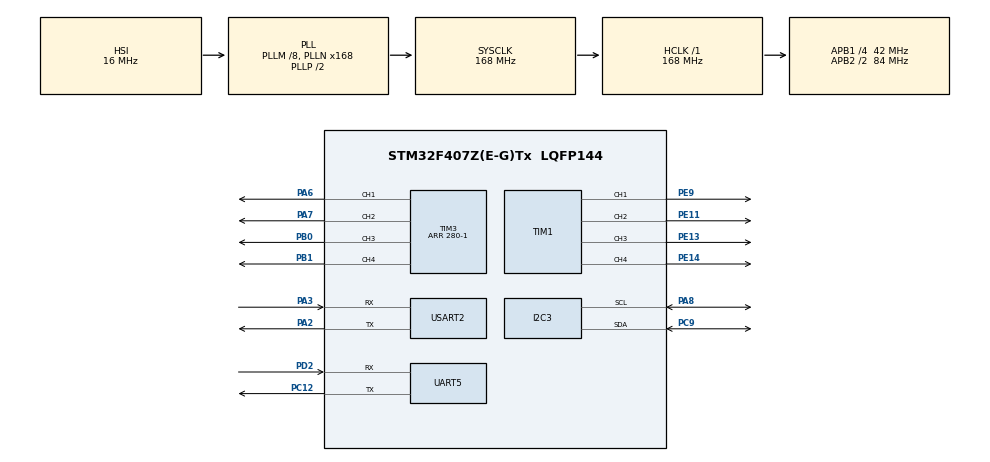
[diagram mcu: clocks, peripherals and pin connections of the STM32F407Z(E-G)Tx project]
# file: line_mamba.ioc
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Mcu.Family=STM32F4
Mcu.Name=STM32F407Z(E-G)Tx
Mcu.Package=LQFP144
NVIC.PriorityGroup=NVIC_PRIORITYGROUP_4
NVIC.USART2_IRQn=true\:5\:0\:false\:false\:true\:true\:true\:true
PA13.Mode=Serial_Wire
PA13.Signal=SYS_JTMS-SWDIO
PA14.Mode=Serial_Wire
PA14.Signal=SYS_JTCK-SWCLK
PA2.Mode=Asynchronous
PA2.Signal=USART2_TX
PA3.Mode=Asynchronous
PA3.Signal=USART2_RX
PA6.Signal=S_TIM3_CH1
PA7.Signal=S_TIM3_CH2
PA8.Mode=I2C
PA8.Signal=I2C3_SCL
PB0.Signal=S_TIM3_CH3
PB1.Signal=S_TIM3_CH4
PC12.Mode=Asynchronous
PC12.Signal=UART5_TX
PC9.Mode=I2C
PC9.Signal=I2C3_SDA
PD2.Mode=Asynchronous
PD2.Signal=UART5_RX
PE11.Signal=S_TIM1_CH2
PE13.Signal=S_TIM1_CH3
PE14.Signal=S_TIM1_CH4
PE9.Signal=S_TIM1_CH1
ProjectManager.HeapSize=0x200
ProjectManager.StackSize=0x400
ProjectManager.TargetToolchain=CMake
RCC.48MHZClocksFreq_Value=48000000
RCC.AHBFreq_Value=168000000
RCC.APB1CLKDivider=RCC_HCLK_DIV4
RCC.APB1Freq_Value=42000000
RCC.APB1TimFreq_Value=84000000
RCC.APB2CLKDivider=RCC_HCLK_DIV2
RCC.APB2Freq_Value=84000000
RCC.APB2TimFreq_Value=168000000
RCC.CortexFreq_Value=168000000
RCC.HSE_VALUE=25000000
RCC.HSI_VALUE=16000000
RCC.LSE_VALUE=32768
RCC.PLLM=8
RCC.PLLN=168
RCC.PLLQ=7
RCC.SYSCLKFreq_VALUE=168000000
RCC.SYSCLKSource=RCC_SYSCLKSOURCE_PLLCLK
RCC.VCOOutputFreq_Value=336000000
SH.S_TIM1_CH1.0=TIM1_CH1,PWM Generation1 CH1
SH.S_TIM1_CH2.0=TIM1_CH2,PWM Generation2 CH2
SH.S_TIM1_CH3.0=TIM1_CH3,PWM Generation3 CH3
SH.S_TIM1_CH4.0=TIM1_CH4,PWM Generation4 CH4
SH.S_TIM3_CH1.0=TIM3_CH1,PWM Generation1 CH1
SH.S_TIM3_CH2.0=TIM3_CH2,PWM Generation2 CH2
SH.S_TIM3_CH3.0=TIM3_CH3,PWM Generation3 CH3
SH.S_TIM3_CH4.0=TIM3_CH4,PWM Generation4 CH4
TIM1.Channel-PWM\ Generation1\ CH1=TIM_CHANNEL_1
TIM1.Channel-PWM\ Generation2\ CH2=TIM_CHANNEL_2
TIM1.Channel-PWM\ Generation3\ CH3=TIM_CHANNEL_3
TIM1.Channel-PWM\ Generation4\ CH4=TIM_CHANNEL_4
TIM3.Channel-PWM\ Generation1\ CH1=TIM_CHANNEL_1
TIM3.Channel-PWM\ Generation2\ CH2=TIM_CHANNEL_2
TIM3.Channel-PWM\ Generation3\ CH3=TIM_CHANNEL_3
TIM3.Channel-PWM\ Generation4\ CH4=TIM_CHANNEL_4
TIM3.Period=280-1
UART5.VirtualMode=Asynchronous
USART2.VirtualMode=VM_ASYNC
board=custom

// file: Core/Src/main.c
/* USER CODE BEGIN Header */
/**
  ******************************************************************************
  * @file           : main.c
  * @brief          : Main program body
  ******************************************************************************
  * @attention
  *
  * Copyright (c) 2026 STMicroelectronics.
  * All rights reserved.
  *
  * This software is licensed under terms that can be found in the LICENSE file
  * in the root directory of this software component.
  * If no LICENSE file comes with this software, it is provided AS-IS.
  *
  ******************************************************************************
  */
/* USER CODE END Header */
#include "main.h"
#include "i2c.h"
#include "tim.h"
#include "usart.h"
#include "gpio.h"

/* USER CODE BEGIN Includes */
#include "mamba_app.h"

/* USER CODE END Includes */

void SystemClock_Config(void);

int main(void)
{

  /* MCU Configuration--------------------------------------------------------*/

  /* Reset of all peripherals, Initializes the Flash interface and the Systick. */
  HAL_Init();

  /* Configure the system clock */
  SystemClock_Config();

  /* Initialize all configured peripherals */
  MX_GPIO_Init();
  MX_TIM1_Init();
  MX_TIM3_Init();
  MX_I2C3_Init();
  MX_UART5_Init();
  MX_USART2_UART_Init();
  /* USER CODE BEGIN 2 */
  MambaApp_Init();

  /* USER CODE END 2 */

  /* Infinite loop */
  while (1)
  {

    /* USER CODE BEGIN 3 */
    MambaApp_Poll();
  }
  /* USER CODE END 3 */
}

void SystemClock_Config(void)
{
  RCC_OscInitTypeDef RCC_OscInitStruct = {0};
  RCC_ClkInitTypeDef RCC_ClkInitStruct = {0};

  /** Configure the main internal regulator output voltage
  */
  __HAL_RCC_PWR_CLK_ENABLE();
  __HAL_PWR_VOLTAGESCALING_CONFIG(PWR_REGULATOR_VOLTAGE_SCALE1);

  /** Initializes the RCC Oscillators according to the specified parameters
  * in the RCC_OscInitTypeDef structure.
  */
  RCC_OscInitStruct.OscillatorType = RCC_OSCILLATORTYPE_HSI;
  RCC_OscInitStruct.HSIState = RCC_HSI_ON;
  RCC_OscInitStruct.HSICalibrationValue = RCC_HSICALIBRATION_DEFAULT;
  RCC_OscInitStruct.PLL.PLLState = RCC_PLL_ON;
  RCC_OscInitStruct.PLL.PLLSource = RCC_PLLSOURCE_HSI;
  RCC_OscInitStruct.PLL.PLLM = 8;
  RCC_OscInitStruct.PLL.PLLN = 168;
  RCC_OscInitStruct.PLL.PLLP = RCC_PLLP_DIV2;
  RCC_OscInitStruct.PLL.PLLQ = 7;
  if (HAL_RCC_OscConfig(&RCC_OscInitStruct) != HAL_OK)
  {
    Error_Handler();
  }

  /** Initializes the CPU, AHB and APB buses clocks
  */
  RCC_ClkInitStruct.ClockType = RCC_CLOCKTYPE_HCLK|RCC_CLOCKTYPE_SYSCLK
                              |RCC_CLOCKTYPE_PCLK1|RCC_CLOCKTYPE_PCLK2;
  RCC_ClkInitStruct.SYSCLKSource = RCC_SYSCLKSOURCE_PLLCLK;
  RCC_ClkInitStruct.AHBCLKDivider = RCC_SYSCLK_DIV1;
  RCC_ClkInitStruct.APB1CLKDivider = RCC_HCLK_DIV4;
  RCC_ClkInitStruct.APB2CLKDivider = RCC_HCLK_DIV2;

  if (HAL_RCC_ClockConfig(&RCC_ClkInitStruct, FLASH_LATENCY_5) != HAL_OK)
  {
    Error_Handler();
  }
}

/* USER CODE BEGIN 4 */
void HAL_UART_RxCpltCallback(UART_HandleTypeDef *huart)
{
  MambaApp_UartRxComplete(huart);
}

void HAL_UART_ErrorCallback(UART_HandleTypeDef *huart)
{
  MambaApp_UartError(huart);
}

/* USER CODE END 4 */

void Error_Handler(void)
{
  /* USER CODE BEGIN Error_Handler_Debug */
  MambaApp_ForceSignalLow();
  __disable_irq();
  while (1)
  {
  }
  /* USER CODE END Error_Handler_Debug */
}
